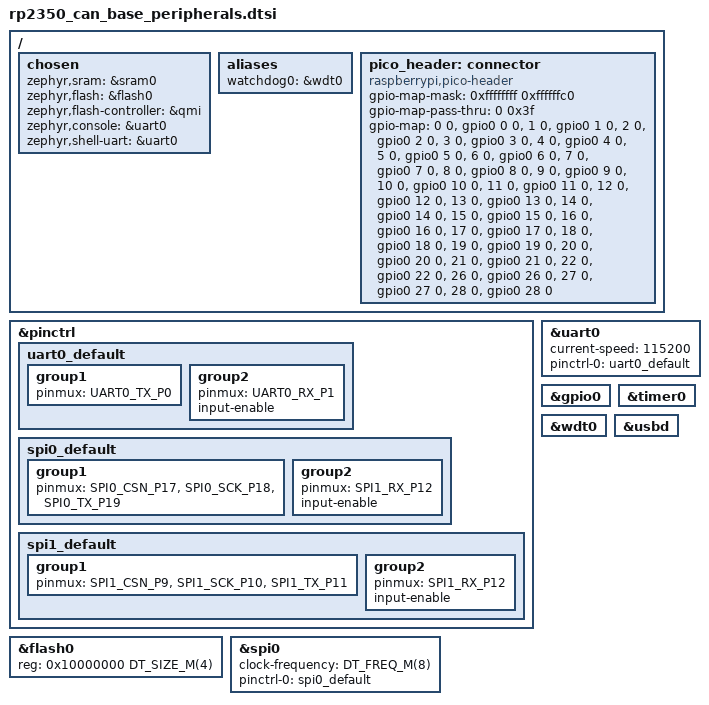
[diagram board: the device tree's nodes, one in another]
/*
 * Copyright (c) 2025 TiaC Systems
 * SPDX-License-Identifier: Apache-2.0
 */

#include <freq.h>
#include <zephyr/dt-bindings/pinctrl/rpi-pico-rp2350a-pinctrl.h>

&pinctrl {
	uart0_default: uart0_default {
		group1 {
			pinmux = <UART0_TX_P0>;
		};
		group2 {
			pinmux = <UART0_RX_P1>;
			input-enable;
		};
	};

	spi0_default: spi0_default {
		group1 {
			pinmux = <SPI0_CSN_P17>, <SPI0_SCK_P18>, <SPI0_TX_P19>;
		};
		group2 {
			pinmux = <SPI1_RX_P12>;
			input-enable;
		};
	};

	spi1_default: spi1_default {
		group1 {
			pinmux = <SPI1_CSN_P9>, <SPI1_SCK_P10>, <SPI1_TX_P11>;
		};
		group2 {
			pinmux = <SPI1_RX_P12>;
			input-enable;
		};
	};	

};

/ {
	chosen {
		zephyr,sram = &sram0;
		zephyr,flash = &flash0;
		zephyr,flash-controller = &qmi;
		zephyr,console = &uart0;
		zephyr,shell-uart = &uart0;
	};

	aliases {
		watchdog0 = &wdt0;
	};

	pico_header: connector {
		compatible = "raspberrypi,pico-header";
		#gpio-cells = <2>;
		gpio-map-mask = <0xffffffff 0xffffffc0>;
		gpio-map-pass-thru = <0 0x3f>;
		gpio-map = <0 0 &gpio0 0 0>,	/* GP0 */
			<1 0 &gpio0 1 0>,	/* GP1 */
			<2 0 &gpio0 2 0>,	/* GP2 */
			<3 0 &gpio0 3 0>,	/* GP3 */
			<4 0 &gpio0 4 0>,	/* GP4 */
			<5 0 &gpio0 5 0>,	/* GP5 */
			<6 0 &gpio0 6 0>,	/* GP6 */
			<7 0 &gpio0 7 0>,	/* GP7 */
			<8 0 &gpio0 8 0>,	/* GP8 */
			<9 0 &gpio0 9 0>,	/* GP9 */
			<10 0 &gpio0 10 0>,	/* GP10 */
			<11 0 &gpio0 11 0>,	/* GP11 */
			<12 0 &gpio0 12 0>,	/* GP12 */
			<13 0 &gpio0 13 0>,	/* GP13 */
			<14 0 &gpio0 14 0>,	/* GP14 */
			<15 0 &gpio0 15 0>,	/* GP15 */
			<16 0 &gpio0 16 0>,	/* GP16 */
			<17 0 &gpio0 17 0>,	/* GP17 */
			<18 0 &gpio0 18 0>,	/* GP18 */
			<19 0 &gpio0 19 0>,	/* GP19 */
			<20 0 &gpio0 20 0>,	/* GP20 */
			<21 0 &gpio0 21 0>,	/* GP21 */
			<22 0 &gpio0 22 0>,	/* GP22 */
			<26 0 &gpio0 26 0>,	/* GP26 */
			<27 0 &gpio0 27 0>,	/* GP27 */
			<28 0 &gpio0 28 0>;	/* GP28 */
	};
};

&flash0 {
	reg = <0x10000000 DT_SIZE_M(4)>;
};

&uart0 {
	current-speed = <115200>;
	status = "okay";
	pinctrl-0 = <&uart0_default>;
	pinctrl-names = "default";
};

gpio0_lo: &gpio0 {
	status = "okay";
};

&spi0 {
	clock-frequency = <DT_FREQ_M(8)>;
	pinctrl-0 = <&spi0_default>;
	pinctrl-names = "default";
};


&timer0 {
	status = "okay";
};

&wdt0 {
	status = "okay";
};

zephyr_udc0: &usbd {
	status = "okay";
};

pico_serial: &uart0 {};
